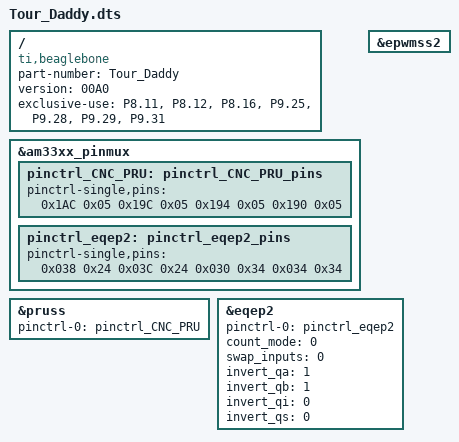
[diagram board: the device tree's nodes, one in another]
/*
* Copyright (C) 2013 Nathaniel R. Lewis - http://nathanielrlewis.com/
*
* This program is free software; you can redistribute it and/or modify
* it under the terms of the GNU General Public License version 2 as
* published by the Free Software Foundation.
*
* CAPE destinée à être implémentée sur le tour de Daddy
*
*/
/dts-v1/;
/plugin/;

/ {
	compatible = "ti,beaglebone", "ti,beaglebone-black";

	/* identification */
	part-number = "Tour_Daddy";
	version     = "00A0";

	/* state the resources this cape uses */
	exclusive-use =
        /* the pin header uses */
        "P8.11",		/* eQEP2 CHB   :  0x034 mode 4*/
        "P8.12",		/* eQEP2 CHA   :  0x030 mode 4*/
        "P8.16",		/* eQEP2 CHI   :  0x038 mode 4*/
        "P9.25",		/* zstep       :  0x1AC mode 5*/
        "P9.28",		/* zdir        :  0x19C mode 5*/
        "P9.29",		/* xstep       :  0x194 mode 5*/
        "P9.31";		/* xdir        :  0x190 mode 5*/

	fragment@0 {
		target = <&am33xx_pinmux>;
		__overlay__ {
			pinctrl_CNC_PRU: pinctrl_CNC_PRU_pins {
				pinctrl-single,pins = <
				/*       Axes     */
				0x1AC 0x05  /* P9_25  PRU 0 out   - zstep */
       			       	0x19C 0x05  /* P9_28  PRU 0 out   - zdir */
       			       	0x194 0x05  /* P9_29  PRU 0 out   - xstep */
       			       	0x190 0x05  /* P9_31  PRU 0 out   - xdir */
				>;
			};
		};
	};

	fragment@1 {
		target = <&am33xx_pinmux>;
		__overlay__ {
			pinctrl_eqep2: pinctrl_eqep2_pins {
				pinctrl-single,pins = <					 				   
				0x038 0x24  /* P8_16 = GPIO1_14 = EQEP2_index, MODE4 */
				0x03C 0x24  /* P8_15 = GPIO1_15 = EQEP2_strobe, MODE4 */
				0x030 0x34  /* P8_12 = GPIO1_12 = EQEP2A_in, MODE4 */
				0x034 0x34  /* P8_11 = GPIO1_13 = EQEP2B_in, MODE4 */
		                /* From: https://groups.google.com/forum/#!searchin/beagleboard/eQep/beagleboard/Orp3tFcNgCc/mYacP_GkCQQJ */
				>;
			};
		};
	};
	
   	fragment@2 {
        	target = <&epwmss2>;
		__overlay__ {
			status = "okay";
		};
	};

	fragment@3 {
		target = <&pruss>;
		__overlay__ {
			status = "okay";
			pinctrl-names = "default";
			pinctrl-0 = <&pinctrl_CNC_PRU>;
		};
	};
	fragment@4 {
    		target = <&eqep2>;
		__overlay__ {
			pinctrl-names = "default";
			pinctrl-0 = <&pinctrl_eqep2>;
			
			count_mode = <0>;  /* 0 - Quadrature mode, normal 90 phase offset cha & chb.  1 - Direction mode.  cha input = clock, chb input = direction */
			swap_inputs = <0>; /* Are channel A and channel B swapped? (0 - no, 1 - yes) */
			invert_qa = <1>;   /* Should we invert the channel A input?  */
			invert_qb = <1>;   /* Should we invert the channel B input? I invert these because my encoder outputs drive transistors that pull down the pins */
			invert_qi = <0>;   /* Should we invert the index input? */
			invert_qs = <0>;   /* Should we invert the strobe input? */
			
			status = "okay";
    		};
	};
};
